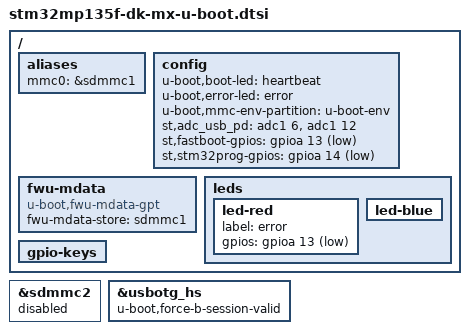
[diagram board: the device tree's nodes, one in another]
// SPDX-License-Identifier: (GPL-2.0-or-later OR BSD-3-Clause)
/*
 * Copyright (C) 2026, STMicroelectronics - All Rights Reserved
 * Author: STM32CubeMX code generation for STMicroelectronics.
 */

/* For more information on Device Tree configuration, please refer to
 * https://wiki.st.com/stm32mpu/wiki/Category:Device_tree_configuration
 */

/* USER CODE BEGIN includes */
#include "stm32mp13-u-boot.dtsi"
/* USER CODE END includes */

/ {

	/* USER CODE BEGIN root */

	aliases{
		mmc0 = &sdmmc1;
	};

	config{
		u-boot,boot-led = "heartbeat";
		u-boot,error-led = "error";
		u-boot,mmc-env-partition = "u-boot-env";
		st,adc_usb_pd = <&adc1 6>, <&adc1 12>;
		st,fastboot-gpios = <&gpioa 13 (GPIO_ACTIVE_LOW | GPIO_PULL_UP)>;
		st,stm32prog-gpios = <&gpioa 14 (GPIO_ACTIVE_LOW | GPIO_PULL_UP)>;
	};

	fwu-mdata{
		compatible = "u-boot,fwu-mdata-gpt";
		fwu-mdata-store = <&sdmmc1>;
	};

	leds{

		led-red{
			label = "error";
			gpios = <&gpioa 13 GPIO_ACTIVE_LOW>;
		};

		led-blue{
			/delete-property/ default-state;
		};
	};

	gpio-keys{
		/delete-node/ button-user;
	};
	/* USER CODE END root */

}; /*root*/

/* USER CODE BEGIN addons */

&sdmmc2 {
	status = "disabled";
};

&usbotg_hs {
	u-boot,force-b-session-valid;
};
/* USER CODE END addons */

